# UICREXTENDED_description register map
Vendor: Nordic Semiconductor; File version: 1
A resource file describing the UICREXTENDED structure
Registers are 32-bit, read-write, reset 0xFFFFFFFF unless marked. A register's access mark holds for its fields unless they carry their own. Offsets are from the block's base; lines under a group give offsets from that group; [hi:lo] are bit positions; {n}, {i} and the like mark numbered series; 'fields as' and 'values as' point back to an identical list; <NAME> marks a mode.

## Memory map
0x00000000 UICREXTENDED_NS size 0x1000 — Extended UICR.

## UICREXTENDED_NS — Extended UICR.
Base 0x00000000
{0x0+0x44*i} GPIO[{i}] (i=0..9) group — Unspecified
  0x00 INSTANCE — Description cluster: Address of the GPIO instance associated with GPIO[n]
    [31:0] ADDRESS — Instance address
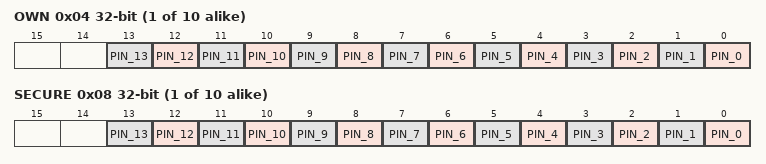
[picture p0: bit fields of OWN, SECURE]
  0x04 OWN — Description cluster: Request ownership of the pins at GPIO port P[n]
    [n] PIN_{n} (n=0..13) — Pin number
      1=NotOwn (Do not own the pin {n}); 0=Own (Own the pin {n})
  0x08 SECURE — Description cluster: Request permission for the pins at GPIO port P[n]
    [n] PIN_{n} (n=0..13) — Pin number
      1=Secure (The pin {n} is secure); 0=NonSecure (The pin {n} is non-secure)
  {0xC+4j} PIN[{j}] (j=0..13) group — Unspecified
    0x00 CTRLSEL — Description cluster: CTRLSEL values for PIN[o] of GPIO port P[n]
      [2:0] CTRLSEL — CTRLSEL value
